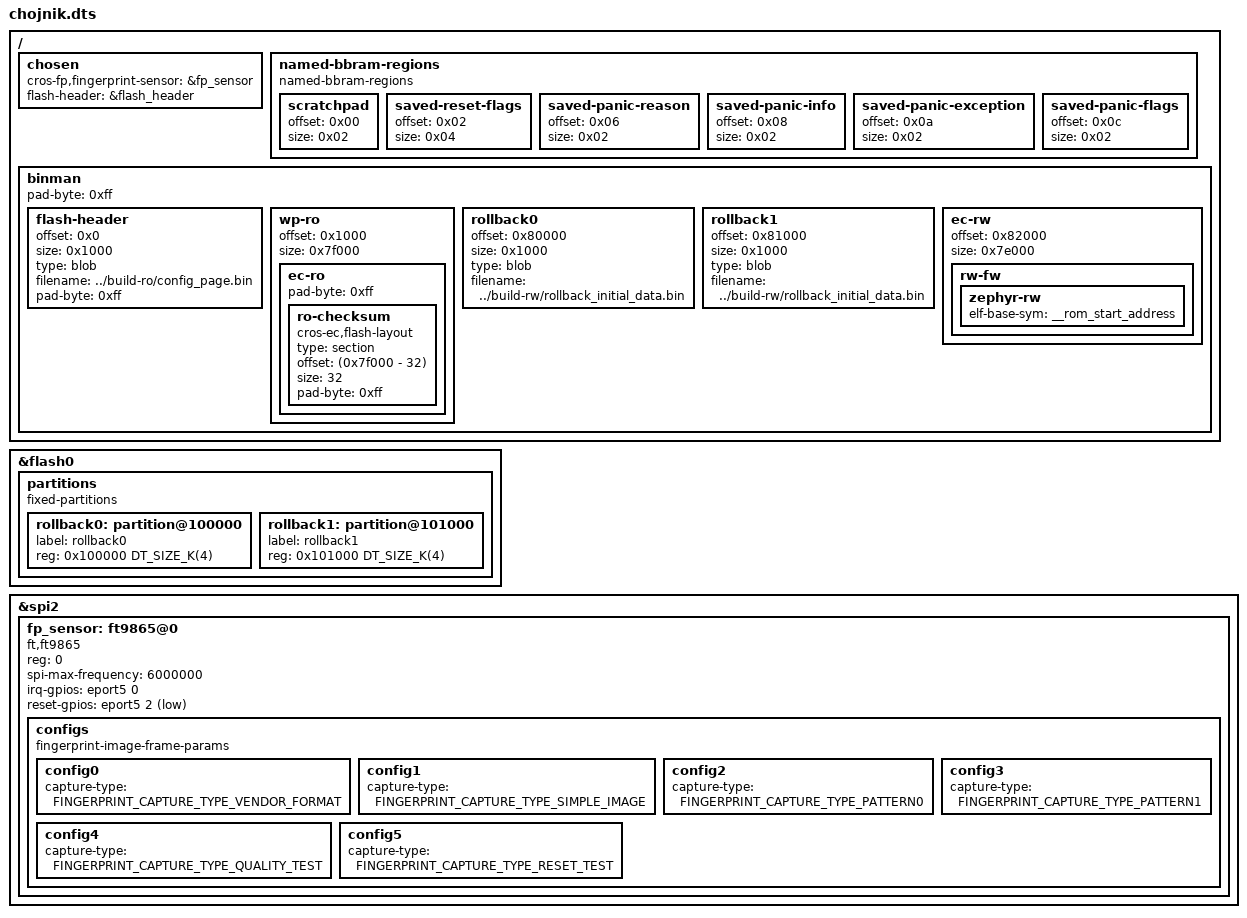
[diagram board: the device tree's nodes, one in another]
/* Copyright 2025 The ChromiumOS Authors.
 * Use of this source code is governed by a BSD-style license that can be
 * found in the LICENSE file.
 */

#include "soc.dtsi"
#include "gpio.dtsi"
#include "rwsig.dtsi"

#include <cros/integrated_fwid.dtsi>

#define FT9865_COMMON_IMAGE_PROPS \
	width = <64>; \
	height = <80>; \
	bits-per-pixel = <8>; \
	frame-size = <5120>; \
	v4l2-pixel-format = "V4L2_PIX_FMT_GREY";

/ {
	chosen {
		cros-fp,fingerprint-sensor = &fp_sensor;
		/* Reference the flash header not to omit it. */
		flash-header = &flash_header;
	};

	named-bbram-regions {
		compatible = "named-bbram-regions";

		scratchpad {
			offset = <0x00>;
			size = <0x02>;
		};
		saved-reset-flags {
			offset = <0x02>;
			size = <0x04>;
		};
		saved-panic-reason {
			offset = <0x06>;
			size = <0x02>;
		};
		saved-panic-info {
			offset = <0x08>;
			size = <0x02>;
		};
		saved-panic-exception {
			offset = <0x0a>;
			size = <0x02>;
		};
		saved-panic-flags {
			offset = <0x0c>;
			size = <0x02>;
		};
	};

	binman {
		flash-header {
			offset = <0x0>;
			size = <0x1000>;
			type = "blob";
			filename = "../build-ro/config_page.bin";
			pad-byte = <0xff>;
		};
		/* The first 4kB of the flash is reserved for the config page */
		wp-ro {
			offset = <0x1000>;
			size = <0x7f000>;
			ec-ro {
				ro-checksum {
					compatible = "cros-ec,flash-layout";
					type = "section";
					offset = <(0x7f000 - 32)>;
					size = <32>;
					pad-byte = <0xff>;
				};
				pad-byte = <0xff>;
			};
		};

		rollback0 {
			offset = <0x80000>;
			size = <0x1000>;
			type = "blob";
			filename = "../build-rw/rollback_initial_data.bin";
		};

		rollback1 {
			offset = <0x81000>;
			size = <0x1000>;
			type = "blob";
			filename = "../build-rw/rollback_initial_data.bin";
		};

		ec-rw {
			offset = <0x82000>;
			size = <0x7e000>;
			rw-fw {
				/*
				 * Clang doesn't emit STT_SECTION symbols (also
				 * called 'section symbols'), so 'rom_start'
				 * symbol is not available. Fortunately, Zephyr
				 * linker scripts provide '__rom_start_address'
				 * symbol which points to the beginning of
				 * 'rom_start' section.
				 */
				zephyr-rw {
					elf-base-sym = "__rom_start_address";
				};
			};
		};
		pad-byte = <0xff>;
	};
};

&flash0 {
	partitions {
		compatible = "fixed-partitions";
		#address-cells = <1>;
		#size-cells = <1>;

		rollback0: partition@100000 {
			label = "rollback0";
			reg = <0x100000 DT_SIZE_K(4)>;
		};

		rollback1: partition@101000 {
			label = "rollback1";
			reg = <0x101000 DT_SIZE_K(4)>;
		};
	};
};

&spi2 {
	fp_sensor: ft9865@0 {
		compatible = "ft,ft9865";
		reg = <0>;
		spi-max-frequency = <6000000>;

		configs {
			compatible = "fingerprint-image-frame-params";
			config0 {
				FT9865_COMMON_IMAGE_PROPS
				capture-type = "FINGERPRINT_CAPTURE_TYPE_VENDOR_FORMAT";
			};
			config1 {
				FT9865_COMMON_IMAGE_PROPS
				capture-type = "FINGERPRINT_CAPTURE_TYPE_SIMPLE_IMAGE";
			};
			config2 {
				FT9865_COMMON_IMAGE_PROPS
				capture-type = "FINGERPRINT_CAPTURE_TYPE_PATTERN0";
			};
			config3 {
				FT9865_COMMON_IMAGE_PROPS
				capture-type = "FINGERPRINT_CAPTURE_TYPE_PATTERN1";
			};
			config4 {
				FT9865_COMMON_IMAGE_PROPS
				capture-type = "FINGERPRINT_CAPTURE_TYPE_QUALITY_TEST";
			};
			config5 {
				FT9865_COMMON_IMAGE_PROPS
				capture-type = "FINGERPRINT_CAPTURE_TYPE_RESET_TEST";
			};
		};

		irq-gpios = <&eport5 0 (GPIO_ACTIVE_HIGH | GPIO_PULL_DOWN)>;
		reset-gpios = <&eport5 2 GPIO_ACTIVE_LOW>;
	};
};
